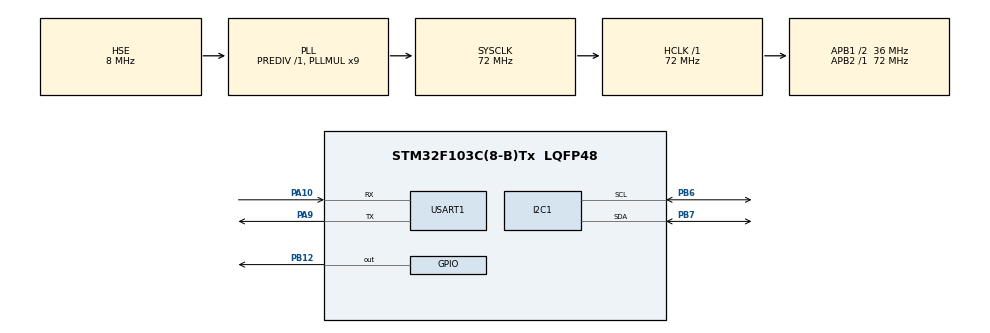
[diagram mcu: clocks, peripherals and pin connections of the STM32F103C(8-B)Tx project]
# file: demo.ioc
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Dma.MEMTOMEM.1.Direction=DMA_MEMORY_TO_MEMORY
Dma.MEMTOMEM.1.Instance=DMA1_Channel1
Dma.MEMTOMEM.1.MemDataAlignment=DMA_MDATAALIGN_BYTE
Dma.MEMTOMEM.1.MemInc=DMA_MINC_ENABLE
Dma.MEMTOMEM.1.Mode=DMA_NORMAL
Dma.MEMTOMEM.1.PeriphDataAlignment=DMA_PDATAALIGN_BYTE
Dma.MEMTOMEM.1.PeriphInc=DMA_PINC_ENABLE
Dma.MEMTOMEM.1.Priority=DMA_PRIORITY_LOW
Dma.MEMTOMEM.2.Direction=DMA_MEMORY_TO_MEMORY
Dma.MEMTOMEM.2.Instance=DMA1_Channel2
Dma.MEMTOMEM.2.MemDataAlignment=DMA_MDATAALIGN_BYTE
Dma.MEMTOMEM.2.MemInc=DMA_MINC_ENABLE
Dma.MEMTOMEM.2.Mode=DMA_NORMAL
Dma.MEMTOMEM.2.PeriphDataAlignment=DMA_PDATAALIGN_BYTE
Dma.MEMTOMEM.2.PeriphInc=DMA_PINC_ENABLE
Dma.MEMTOMEM.2.Priority=DMA_PRIORITY_LOW
Dma.Request0=USART1_TX
Dma.Request1=MEMTOMEM
Dma.Request2=MEMTOMEM
Dma.USART1_TX.0.Direction=DMA_MEMORY_TO_PERIPH
Dma.USART1_TX.0.Instance=DMA1_Channel4
Dma.USART1_TX.0.MemDataAlignment=DMA_MDATAALIGN_BYTE
Dma.USART1_TX.0.MemInc=DMA_MINC_ENABLE
Dma.USART1_TX.0.Mode=DMA_CIRCULAR
Dma.USART1_TX.0.PeriphDataAlignment=DMA_PDATAALIGN_BYTE
Dma.USART1_TX.0.PeriphInc=DMA_PINC_DISABLE
Dma.USART1_TX.0.Priority=DMA_PRIORITY_LOW
I2C1.I2C_Mode=I2C_Fast
Mcu.Family=STM32F1
Mcu.Name=STM32F103C(8-B)Tx
Mcu.Package=LQFP48
NVIC.DMA1_Channel4_IRQn=true\:0\:0\:false\:false\:true\:false\:true
NVIC.I2C1_ER_IRQn=true\:0\:0\:false\:false\:true\:true\:true
NVIC.I2C1_EV_IRQn=true\:0\:0\:false\:false\:true\:true\:true
NVIC.PriorityGroup=NVIC_PRIORITYGROUP_4
NVIC.TIM2_IRQn=true\:0\:0\:false\:false\:true\:true\:true
NVIC.USART1_IRQn=true\:0\:0\:false\:false\:true\:true\:true
PA10.Mode=Asynchronous
PA10.Signal=USART1_RX
PA9.Mode=Asynchronous
PA9.Signal=USART1_TX
PB12.PinState=GPIO_PIN_RESET
PB12.Signal=GPIO_Output
PB6.GPIO_Pu=GPIO_PULLUP
PB6.Mode=I2C
PB6.Signal=I2C1_SCL
PB7.GPIO_Pu=GPIO_PULLUP
PB7.Mode=I2C
PB7.Signal=I2C1_SDA
PD0-OSC_IN.Mode=HSE-External-Oscillator
PD0-OSC_IN.Signal=RCC_OSC_IN
PD1-OSC_OUT.Mode=HSE-External-Oscillator
PD1-OSC_OUT.Signal=RCC_OSC_OUT
ProjectManager.HeapSize=0x200
ProjectManager.StackSize=0x400
ProjectManager.TargetToolchain=Makefile
RCC.AHBFreq_Value=72000000
RCC.APB1CLKDivider=RCC_HCLK_DIV2
RCC.APB1Freq_Value=36000000
RCC.APB1TimFreq_Value=72000000
RCC.APB2Freq_Value=72000000
RCC.APB2TimFreq_Value=72000000
RCC.HCLKFreq_Value=72000000
RCC.PLLMUL=RCC_PLL_MUL9
RCC.PLLSourceVirtual=RCC_PLLSOURCE_HSE
RCC.SYSCLKFreq_VALUE=72000000
RCC.SYSCLKSource=RCC_SYSCLKSOURCE_PLLCLK
RCC.TimSys_Div=SYSTICK_CLKSOURCE_HCLK_DIV8
RCC.USBFreq_Value=72000000
TIM2.AutoReloadPreload=TIM_AUTORELOAD_PRELOAD_ENABLE
TIM2.Period=4999
TIM2.Prescaler=7199
USART1.VirtualMode=VM_ASYNC
VP_SYS_VS_ND.Mode=No_Debug
VP_TIM2_VS_ClockSourceINT.Mode=Internal
board=custom

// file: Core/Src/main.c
/* USER CODE BEGIN Header */
/**
  ******************************************************************************
  * @file           : main.c
  * @brief          : Main program body
  ******************************************************************************
  * @attention
  *
  * <h2><center>&copy; Copyright (c) 2021 STMicroelectronics.
  * All rights reserved.</center></h2>
  *
  * This software component is licensed by ST under BSD 3-Clause license,
  * the "License"; You may not use this file except in compliance with the
  * License. You may obtain a copy of the License at:
  *                        opensource.org/licenses/BSD-3-Clause
  *
  ******************************************************************************
  */
/* USER CODE END Header */
#include "main.h"

/* USER CODE BEGIN Includes */
#include <math.h>
#include "oled.h"
#include "mysetp.h"
/* USER CODE END Includes */

I2C_HandleTypeDef hi2c1;

TIM_HandleTypeDef htim2;

UART_HandleTypeDef huart1;
DMA_HandleTypeDef hdma_usart1_tx;

DMA_HandleTypeDef hdma_memtomem_dma1_channel1;
DMA_HandleTypeDef hdma_memtomem_dma1_channel2;

void SystemClock_Config(void);
static void MX_GPIO_Init(void);
static void MX_I2C1_Init(void);
static void MX_TIM2_Init(void);
static void MX_DMA_Init(void);
static void MX_USART1_UART_Init(void);

int main(void)
{

  /* MCU Configuration--------------------------------------------------------*/

  /* Reset of all peripherals, Initializes the Flash interface and the Systick. */
  HAL_Init();

  /* Configure the system clock */
  SystemClock_Config();

  /* Initialize all configured peripherals */
  MX_GPIO_Init();
  MX_I2C1_Init();
  MX_TIM2_Init();
  MX_DMA_Init();
  MX_USART1_UART_Init();

  /* Infinite loop */
  while (1)
  {

    /* USER CODE BEGIN 3 */

    //oledINIT(&hi2c1);
    //HAL_GPIO_WritePin(GPIOB, GPIO_PIN_12, GPIO_PIN_SET);
   mysetp();

   while(1){}
  }
  /* USER CODE END 3 */
}

void SystemClock_Config(void)
{
  RCC_OscInitTypeDef RCC_OscInitStruct = {0};
  RCC_ClkInitTypeDef RCC_ClkInitStruct = {0};

  /** Initializes the RCC Oscillators according to the specified parameters
  * in the RCC_OscInitTypeDef structure.
  */
  RCC_OscInitStruct.OscillatorType = RCC_OSCILLATORTYPE_HSE;
  RCC_OscInitStruct.HSEState = RCC_HSE_ON;
  RCC_OscInitStruct.HSEPredivValue = RCC_HSE_PREDIV_DIV1;
  RCC_OscInitStruct.HSIState = RCC_HSI_ON;
  RCC_OscInitStruct.PLL.PLLState = RCC_PLL_ON;
  RCC_OscInitStruct.PLL.PLLSource = RCC_PLLSOURCE_HSE;
  RCC_OscInitStruct.PLL.PLLMUL = RCC_PLL_MUL9;
  if (HAL_RCC_OscConfig(&RCC_OscInitStruct) != HAL_OK)
  {
    Error_Handler();
  }
  /** Initializes the CPU, AHB and APB buses clocks
  */
  RCC_ClkInitStruct.ClockType = RCC_CLOCKTYPE_HCLK|RCC_CLOCKTYPE_SYSCLK
                              |RCC_CLOCKTYPE_PCLK1|RCC_CLOCKTYPE_PCLK2;
  RCC_ClkInitStruct.SYSCLKSource = RCC_SYSCLKSOURCE_PLLCLK;
  RCC_ClkInitStruct.AHBCLKDivider = RCC_SYSCLK_DIV1;
  RCC_ClkInitStruct.APB1CLKDivider = RCC_HCLK_DIV2;
  RCC_ClkInitStruct.APB2CLKDivider = RCC_HCLK_DIV1;

  if (HAL_RCC_ClockConfig(&RCC_ClkInitStruct, FLASH_LATENCY_2) != HAL_OK)
  {
    Error_Handler();
  }
}

static void MX_I2C1_Init(void)
{

  hi2c1.Instance = I2C1;
  hi2c1.Init.ClockSpeed = 400000;
  hi2c1.Init.DutyCycle = I2C_DUTYCYCLE_2;
  hi2c1.Init.OwnAddress1 = 0;
  hi2c1.Init.AddressingMode = I2C_ADDRESSINGMODE_7BIT;
  hi2c1.Init.DualAddressMode = I2C_DUALADDRESS_DISABLE;
  hi2c1.Init.OwnAddress2 = 0;
  hi2c1.Init.GeneralCallMode = I2C_GENERALCALL_DISABLE;
  hi2c1.Init.NoStretchMode = I2C_NOSTRETCH_DISABLE;
  if (HAL_I2C_Init(&hi2c1) != HAL_OK)
  {
    Error_Handler();
  }

}

static void MX_TIM2_Init(void)
{

  TIM_ClockConfigTypeDef sClockSourceConfig = {0};
  TIM_MasterConfigTypeDef sMasterConfig = {0};

  htim2.Instance = TIM2;
  htim2.Init.Prescaler = 7199;
  htim2.Init.CounterMode = TIM_COUNTERMODE_UP;
  htim2.Init.Period = 4999;
  htim2.Init.ClockDivision = TIM_CLOCKDIVISION_DIV1;
  htim2.Init.AutoReloadPreload = TIM_AUTORELOAD_PRELOAD_ENABLE;
  if (HAL_TIM_Base_Init(&htim2) != HAL_OK)
  {
    Error_Handler();
  }
  sClockSourceConfig.ClockSource = TIM_CLOCKSOURCE_INTERNAL;
  if (HAL_TIM_ConfigClockSource(&htim2, &sClockSourceConfig) != HAL_OK)
  {
    Error_Handler();
  }
  sMasterConfig.MasterOutputTrigger = TIM_TRGO_RESET;
  sMasterConfig.MasterSlaveMode = TIM_MASTERSLAVEMODE_DISABLE;
  if (HAL_TIMEx_MasterConfigSynchronization(&htim2, &sMasterConfig) != HAL_OK)
  {
    Error_Handler();
  }

}

static void MX_USART1_UART_Init(void)
{

  huart1.Instance = USART1;
  huart1.Init.BaudRate = 115200;
  huart1.Init.WordLength = UART_WORDLENGTH_8B;
  huart1.Init.StopBits = UART_STOPBITS_1;
  huart1.Init.Parity = UART_PARITY_NONE;
  huart1.Init.Mode = UART_MODE_TX_RX;
  huart1.Init.HwFlowCtl = UART_HWCONTROL_NONE;
  huart1.Init.OverSampling = UART_OVERSAMPLING_16;
  if (HAL_UART_Init(&huart1) != HAL_OK)
  {
    Error_Handler();
  }

}

static void MX_DMA_Init(void)
{

  /* DMA controller clock enable */
  __HAL_RCC_DMA1_CLK_ENABLE();

  /* Configure DMA request hdma_memtomem_dma1_channel1 on DMA1_Channel1 */
  hdma_memtomem_dma1_channel1.Instance = DMA1_Channel1;
  hdma_memtomem_dma1_channel1.Init.Direction = DMA_MEMORY_TO_MEMORY;
  hdma_memtomem_dma1_channel1.Init.PeriphInc = DMA_PINC_ENABLE;
  hdma_memtomem_dma1_channel1.Init.MemInc = DMA_MINC_ENABLE;
  hdma_memtomem_dma1_channel1.Init.PeriphDataAlignment = DMA_PDATAALIGN_BYTE;
  hdma_memtomem_dma1_channel1.Init.MemDataAlignment = DMA_MDATAALIGN_BYTE;
  hdma_memtomem_dma1_channel1.Init.Mode = DMA_NORMAL;
  hdma_memtomem_dma1_channel1.Init.Priority = DMA_PRIORITY_LOW;
  if (HAL_DMA_Init(&hdma_memtomem_dma1_channel1) != HAL_OK)
  {
    Error_Handler( );
  }

  /* Configure DMA request hdma_memtomem_dma1_channel2 on DMA1_Channel2 */
  hdma_memtomem_dma1_channel2.Instance = DMA1_Channel2;
  hdma_memtomem_dma1_channel2.Init.Direction = DMA_MEMORY_TO_MEMORY;
  hdma_memtomem_dma1_channel2.Init.PeriphInc = DMA_PINC_ENABLE;
  hdma_memtomem_dma1_channel2.Init.MemInc = DMA_MINC_ENABLE;
  hdma_memtomem_dma1_channel2.Init.PeriphDataAlignment = DMA_PDATAALIGN_BYTE;
  hdma_memtomem_dma1_channel2.Init.MemDataAlignment = DMA_MDATAALIGN_BYTE;
  hdma_memtomem_dma1_channel2.Init.Mode = DMA_NORMAL;
  hdma_memtomem_dma1_channel2.Init.Priority = DMA_PRIORITY_LOW;
  if (HAL_DMA_Init(&hdma_memtomem_dma1_channel2) != HAL_OK)
  {
    Error_Handler( );
  }

  /* DMA interrupt init */
  /* DMA1_Channel4_IRQn interrupt configuration */
  HAL_NVIC_SetPriority(DMA1_Channel4_IRQn, 0, 0);
  HAL_NVIC_EnableIRQ(DMA1_Channel4_IRQn);

}

static void MX_GPIO_Init(void)
{
  GPIO_InitTypeDef GPIO_InitStruct = {0};

  /* GPIO Ports Clock Enable */
  __HAL_RCC_GPIOD_CLK_ENABLE();
  __HAL_RCC_GPIOB_CLK_ENABLE();
  __HAL_RCC_GPIOA_CLK_ENABLE();

  /*Configure GPIO pin Output Level */
  HAL_GPIO_WritePin(GPIOB, GPIO_PIN_12, GPIO_PIN_RESET);

  /*Configure GPIO pin : PB12 */
  GPIO_InitStruct.Pin = GPIO_PIN_12;
  GPIO_InitStruct.Mode = GPIO_MODE_OUTPUT_PP;
  GPIO_InitStruct.Pull = GPIO_NOPULL;
  GPIO_InitStruct.Speed = GPIO_SPEED_FREQ_LOW;
  HAL_GPIO_Init(GPIOB, &GPIO_InitStruct);

}

void Error_Handler(void)
{
  /* USER CODE BEGIN Error_Handler_Debug */
  /* User can add his own implementation to report the HAL error return state */
  __disable_irq();
  while (1)
  {
         HAL_GPIO_WritePin(GPIOB, GPIO_PIN_12, GPIO_PIN_SET);
  }
  /* USER CODE END Error_Handler_Debug */
}

/************************ (C) COPYRIGHT STMicroelectronics *****END OF FILE****/
